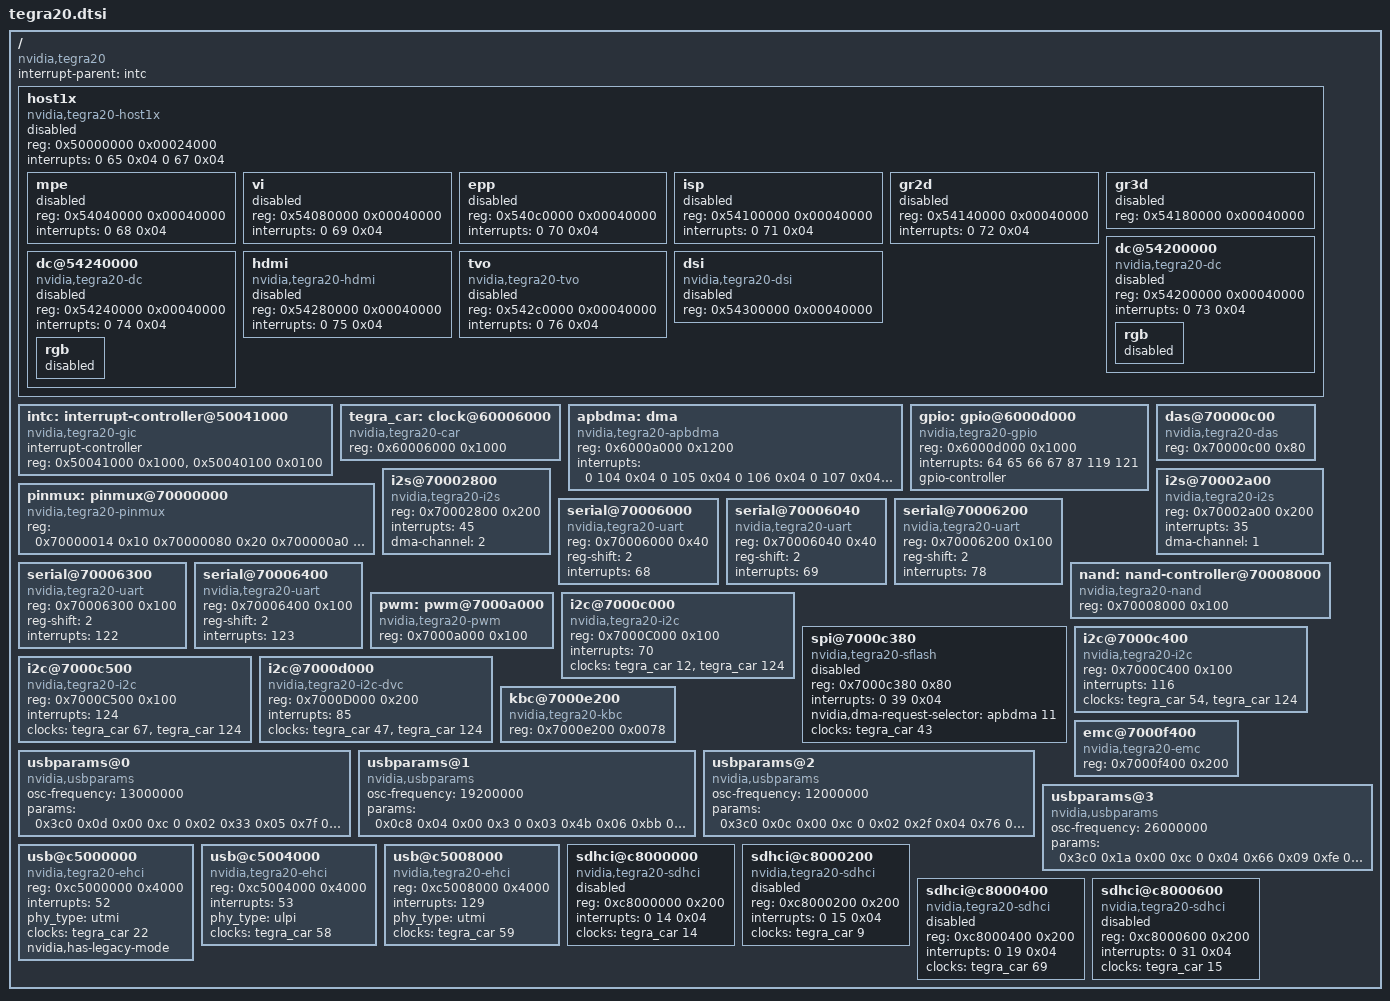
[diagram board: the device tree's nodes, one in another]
/include/ "skeleton.dtsi"

/ {
	compatible = "nvidia,tegra20";
	interrupt-parent = <&intc>;

	host1x {
		compatible = "nvidia,tegra20-host1x", "simple-bus";
		reg = <0x50000000 0x00024000>;
		interrupts = <0 65 0x04   /* mpcore syncpt */
			      0 67 0x04>; /* mpcore general */
		status = "disabled";

		#address-cells = <1>;
		#size-cells = <1>;

		ranges = <0x54000000 0x54000000 0x04000000>;

		/* video-encoding/decoding */
		mpe {
			reg = <0x54040000 0x00040000>;
			interrupts = <0 68 0x04>;
			status = "disabled";
		};

		/* video input */
		vi {
			reg = <0x54080000 0x00040000>;
			interrupts = <0 69 0x04>;
			status = "disabled";
		};

		/* EPP */
		epp {
			reg = <0x540c0000 0x00040000>;
			interrupts = <0 70 0x04>;
			status = "disabled";
		};

		/* ISP */
		isp {
			reg = <0x54100000 0x00040000>;
			interrupts = <0 71 0x04>;
			status = "disabled";
		};

		/* 2D engine */
		gr2d {
			reg = <0x54140000 0x00040000>;
			interrupts = <0 72 0x04>;
			status = "disabled";
		};

		/* 3D engine */
		gr3d {
			reg = <0x54180000 0x00040000>;
			status = "disabled";
		};

		/* display controllers */
		dc@54200000 {
			compatible = "nvidia,tegra20-dc";
			reg = <0x54200000 0x00040000>;
			interrupts = <0 73 0x04>;
			status = "disabled";

			rgb {
				status = "disabled";
			};
		};

		dc@54240000 {
			compatible = "nvidia,tegra20-dc";
			reg = <0x54240000 0x00040000>;
			interrupts = <0 74 0x04>;
			status = "disabled";

			rgb {
				status = "disabled";
			};
		};

		/* outputs */
		hdmi {
			compatible = "nvidia,tegra20-hdmi";
			reg = <0x54280000 0x00040000>;
			interrupts = <0 75 0x04>;
			status = "disabled";
		};

		tvo {
			compatible = "nvidia,tegra20-tvo";
			reg = <0x542c0000 0x00040000>;
			interrupts = <0 76 0x04>;
			status = "disabled";
		};

		dsi {
			compatible = "nvidia,tegra20-dsi";
			reg = <0x54300000 0x00040000>;
			status = "disabled";
		};
	};

	intc: interrupt-controller@50041000 {
		compatible = "nvidia,tegra20-gic";
		interrupt-controller;
		#interrupt-cells = <1>;
		reg = < 0x50041000 0x1000 >,
		      < 0x50040100 0x0100 >;
	};

	tegra_car: clock@60006000 {
		compatible = "nvidia,tegra20-car";
		reg = <0x60006000 0x1000>;
		#clock-cells = <1>;
	};

	apbdma: dma {
		compatible = "nvidia,tegra20-apbdma";
		reg = <0x6000a000 0x1200>;
		interrupts = <0 104 0x04
			      0 105 0x04
			      0 106 0x04
			      0 107 0x04
			      0 108 0x04
			      0 109 0x04
			      0 110 0x04
			      0 111 0x04
			      0 112 0x04
			      0 113 0x04
			      0 114 0x04
			      0 115 0x04
			      0 116 0x04
			      0 117 0x04
			      0 118 0x04
			      0 119 0x04>;
	};

	gpio: gpio@6000d000 {
		compatible = "nvidia,tegra20-gpio";
		reg = < 0x6000d000 0x1000 >;
		interrupts = < 64 65 66 67 87 119 121 >;
		#gpio-cells = <2>;
		gpio-controller;
	};

	pinmux: pinmux@70000000 {
		compatible = "nvidia,tegra20-pinmux";
		reg = < 0x70000014 0x10    /* Tri-state registers */
			0x70000080 0x20    /* Mux registers */
			0x700000a0 0x14    /* Pull-up/down registers */
			0x70000868 0xa8 >; /* Pad control registers */
	};

	das@70000c00 {
		#address-cells = <1>;
		#size-cells = <0>;
		compatible = "nvidia,tegra20-das";
		reg = <0x70000c00 0x80>;
	};

	i2s@70002800 {
		#address-cells = <1>;
		#size-cells = <0>;
		compatible = "nvidia,tegra20-i2s";
		reg = <0x70002800 0x200>;
		interrupts = < 45 >;
		dma-channel = < 2 >;
	};

	i2s@70002a00 {
		#address-cells = <1>;
		#size-cells = <0>;
		compatible = "nvidia,tegra20-i2s";
		reg = <0x70002a00 0x200>;
		interrupts = < 35 >;
		dma-channel = < 1 >;
	};

	serial@70006000 {
		compatible = "nvidia,tegra20-uart";
		reg = <0x70006000 0x40>;
		reg-shift = <2>;
		interrupts = < 68 >;
	};

	serial@70006040 {
		compatible = "nvidia,tegra20-uart";
		reg = <0x70006040 0x40>;
		reg-shift = <2>;
		interrupts = < 69 >;
	};

	serial@70006200 {
		compatible = "nvidia,tegra20-uart";
		reg = <0x70006200 0x100>;
		reg-shift = <2>;
		interrupts = < 78 >;
	};

	serial@70006300 {
		compatible = "nvidia,tegra20-uart";
		reg = <0x70006300 0x100>;
		reg-shift = <2>;
		interrupts = < 122 >;
	};

	serial@70006400 {
		compatible = "nvidia,tegra20-uart";
		reg = <0x70006400 0x100>;
		reg-shift = <2>;
		interrupts = < 123 >;
	};

	nand: nand-controller@70008000 {
		#address-cells = <1>;
		#size-cells = <0>;
		compatible = "nvidia,tegra20-nand";
		reg = <0x70008000 0x100>;
	};

	pwm: pwm@7000a000 {
		compatible = "nvidia,tegra20-pwm";
		reg = <0x7000a000 0x100>;
		#pwm-cells = <2>;
	};

	i2c@7000c000 {
		#address-cells = <1>;
		#size-cells = <0>;
		compatible = "nvidia,tegra20-i2c";
		reg = <0x7000C000 0x100>;
		interrupts = < 70 >;
		/* PERIPH_ID_I2C1, PLL_P_OUT3 */
		clocks = <&tegra_car 12>, <&tegra_car 124>;
	};

	spi@7000c380 {
		compatible = "nvidia,tegra20-sflash";
		reg = <0x7000c380 0x80>;
		interrupts = <0 39 0x04>;
		nvidia,dma-request-selector = <&apbdma 11>;
		#address-cells = <1>;
		#size-cells = <0>;
		status = "disabled";
		/* PERIPH_ID_SPI1, PLLP_OUT0 */
		clocks = <&tegra_car 43>;
	};

	i2c@7000c400 {
		#address-cells = <1>;
		#size-cells = <0>;
		compatible = "nvidia,tegra20-i2c";
		reg = <0x7000C400 0x100>;
		interrupts = < 116 >;
		/* PERIPH_ID_I2C2, PLL_P_OUT3 */
		clocks = <&tegra_car 54>, <&tegra_car 124>;
	};

	i2c@7000c500 {
		#address-cells = <1>;
		#size-cells = <0>;
		compatible = "nvidia,tegra20-i2c";
		reg = <0x7000C500 0x100>;
		interrupts = < 124 >;
		/* PERIPH_ID_I2C3, PLL_P_OUT3 */
		clocks = <&tegra_car 67>, <&tegra_car 124>;
	};

	i2c@7000d000 {
		#address-cells = <1>;
		#size-cells = <0>;
		compatible = "nvidia,tegra20-i2c-dvc";
		reg = <0x7000D000 0x200>;
		interrupts = < 85 >;
		/* PERIPH_ID_DVC_I2C, PLL_P_OUT3 */
		clocks = <&tegra_car 47>, <&tegra_car 124>;
	};

	kbc@7000e200 {
		compatible = "nvidia,tegra20-kbc";
		reg = <0x7000e200 0x0078>;
	};

	emc@7000f400 {
		#address-cells = < 1 >;
		#size-cells = < 0 >;
		compatible = "nvidia,tegra20-emc";
		reg = <0x7000f400 0x200>;
	};

/* This table has USB timing parameters for each Oscillator frequency we
 * support. There are four sets of values:
 *
 * 1. PLLU configuration information (reference clock is osc/clk_m and
 * PLLU-FOs are fixed at 12MHz/60MHz/480MHz).
 *
 *  Reference frequency     13.0MHz      19.2MHz      12.0MHz      26.0MHz
 *  ----------------------------------------------------------------------
 *      DIVN                960 (0x3c0)  200 (0c8)    960 (3c0h)   960 (3c0)
 *      DIVM                13 (0d)      4 (04)       12 (0c)      26 (1a)
 * Filter frequency (MHz)   1            4.8          6            2
 * CPCON                    1100b        0011b        1100b        1100b
 * LFCON0                   0            0            0            0
 *
 * 2. PLL CONFIGURATION & PARAMETERS for different clock generators:
 *
 * Reference frequency     13.0MHz         19.2MHz         12.0MHz     26.0MHz
 * ---------------------------------------------------------------------------
 * PLLU_ENABLE_DLY_COUNT   02 (0x02)       03 (03)         02 (02)     04 (04)
 * PLLU_STABLE_COUNT       51 (33)         75 (4B)         47 (2F)    102 (66)
 * PLL_ACTIVE_DLY_COUNT    05 (05)         06 (06)         04 (04)     09 (09)
 * XTAL_FREQ_COUNT        127 (7F)        187 (BB)        118 (76)    254 (FE)
 *
 * 3. Debounce values IdDig, Avalid, Bvalid, VbusValid, VbusWakeUp, and
 * SessEnd. Each of these signals have their own debouncer and for each of
 * those one out of two debouncing times can be chosen (BIAS_DEBOUNCE_A or
 * BIAS_DEBOUNCE_B).
 *
 * The values of DEBOUNCE_A and DEBOUNCE_B are calculated as follows:
 *    0xffff -> No debouncing at all
 *    <n> ms = <n> * 1000 / (1/19.2MHz) / 4
 *
 * So to program a 10 ms debounce for BIAS_DEBOUNCE_A, we have:
 * BIAS_DEBOUNCE_A[15:0] = 10 * 1000 * 19.2 / 4  = 48000 = 0xBB80
 *
 * We need to use only DebounceA for BOOTROM. We don't need the DebounceB
 * values, so we can keep those to default.
 *
 * 4. The 20 microsecond delay after bias cell operation.
 *    UTMIP_BIAS_PAD_TRK_COUNT
 *
 * enum {
 *	PARAM_DIVN,                     // PLL FEEDBACK DIVIDER
 *	PARAM_DIVM,                     // PLL INPUT DIVIDER
 *	PARAM_DIVP,                     // POST DIVIDER (2^N)
 *	PARAM_CPCON,                    // BASE PLLC CHARGE Pump setup ctrl
 *	PARAM_LFCON,                    // BASE PLLC LOOP FILter setup ctrl
 *	PARAM_ENABLE_DELAY_COUNT,       // PLL-U Enable Delay Count
 *	PARAM_STABLE_COUNT,             // PLL-U STABLE count
 *	PARAM_ACTIVE_DELAY_COUNT,       // PLL-U Active delay count
 *	PARAM_XTAL_FREQ_COUNT,          // PLL-U XTAL frequency count
 *	PARAM_DEBOUNCE_A_TIME,          // 10MS DELAY for BIAS_DEBOUNCE_A
 *	PARAM_BIAS_TIME,                // 20US DELAY AFter bias cell op
 *					// UTMIP_BIAS_PAD_TRK_COUNT
 *};
 */
	usbparams@0 {
		compatible = "nvidia,usbparams";
		osc-frequency = <13000000>;
		/* DivN, DivM, DivP, CPCON, LFCON, Delays      Debounce, Bias */
		params = <0x3c0 0x0d 0x00 0xc 0  0x02 0x33 0x05 0x7f  0x7ef4 5>;
	};

	usbparams@1 {
		compatible = "nvidia,usbparams";
		osc-frequency = <19200000>;
		params = <0x0c8 0x04 0x00 0x3 0  0x03 0x4b 0x06 0xbb  0xbb80 7>;
	};

	usbparams@2 {
		compatible = "nvidia,usbparams";
		osc-frequency = <12000000>;
		params = <0x3c0 0x0c 0x00 0xc 0  0x02 0x2f 0x04 0x76  0x7530 5>;
	};

	usbparams@3 {
		compatible = "nvidia,usbparams";
		osc-frequency = <26000000>;
		params = <0x3c0 0x1a 0x00 0xc 0  0x04 0x66 0x09 0xfe  0xfde8 9>;
	};

	usb@c5000000 {
		compatible = "nvidia,tegra20-ehci", "usb-ehci";
		reg = <0xc5000000 0x4000>;
		interrupts = < 52 >;
		phy_type = "utmi";
		clocks = <&tegra_car 22>;	/* PERIPH_ID_USBD */
		nvidia,has-legacy-mode;
	};

	usb@c5004000 {
		compatible = "nvidia,tegra20-ehci", "usb-ehci";
		reg = <0xc5004000 0x4000>;
		interrupts = < 53 >;
		phy_type = "ulpi";
		clocks = <&tegra_car 58>;	/* PERIPH_ID_USB2 */
	};

	usb@c5008000 {
		compatible = "nvidia,tegra20-ehci", "usb-ehci";
		reg = <0xc5008000 0x4000>;
		interrupts = < 129 >;
		phy_type = "utmi";
		clocks = <&tegra_car 59>;	/* PERIPH_ID_USB3 */
	};

	sdhci@c8000000 {
		compatible = "nvidia,tegra20-sdhci";
		reg = <0xc8000000 0x200>;
		interrupts = <0 14 0x04>;
		clocks = <&tegra_car 14>;
		status = "disabled";
	};

	sdhci@c8000200 {
		compatible = "nvidia,tegra20-sdhci";
		reg = <0xc8000200 0x200>;
		interrupts = <0 15 0x04>;
		clocks = <&tegra_car 9>;
		status = "disabled";
	};

	sdhci@c8000400 {
		compatible = "nvidia,tegra20-sdhci";
		reg = <0xc8000400 0x200>;
		interrupts = <0 19 0x04>;
		clocks = <&tegra_car 69>;
		status = "disabled";
	};

	sdhci@c8000600 {
		compatible = "nvidia,tegra20-sdhci";
		reg = <0xc8000600 0x200>;
		interrupts = <0 31 0x04>;
		clocks = <&tegra_car 15>;
		status = "disabled";
	};
};
